# MIMXRT685S_cm33 register map
Vendor: nxp.com; File version: 1.0
CPU: CM33 r2p0, little endian, MPU, FPU, VTOR, 3 interrupt priority bits
Registers are 32-bit, read-write, reset 0x0 unless marked. A register's access mark holds for its fields unless they carry their own. Offsets are from the block's base; [hi:lo] are bit positions; {n}, {i} and the like mark numbered series.

## CMP
Base 0x40139000
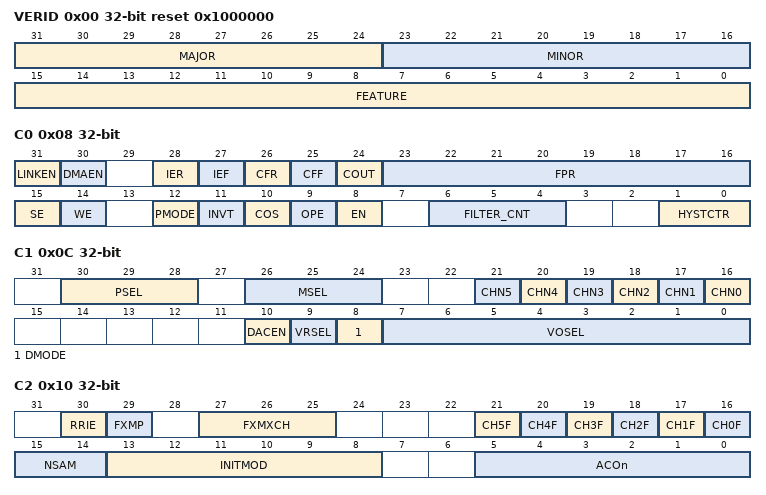
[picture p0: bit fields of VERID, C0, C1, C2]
0x00 VERID ro reset 0x1000000 — Version ID Register
  [31:24] MAJOR — Major Version Number. This read only field returns the major version number for the module specification.
  [23:16] MINOR — Minor Version Number. This read only field returns the minor version number for the module specification.
  [15:0] FEATURE — Feature Specification Number. This read only filed returns the feature set number.
0x04 PARAM ro — Parameter Register
  [31:0] PARAM — Parameter Registers. This read only filed returns the feature parameters implemented along with the Version ID register.
0x08 C0 — CMP Control Register 0
  [31] LINKEN — CMP to DAC link enable.
    0=CMP to DAC link is disabled; 1=CMP to DAC link is enabled
  [30] DMAEN — DMA Enable
    0=DMA is disabled; 1=DMA is enabled
  [28] IER — Comparator Interrupt Enable Rising
    0=Interrupt is disabled; 1=Interrupt is enabled
  [27] IEF — Comparator Interrupt Enable Falling
    0=Interrupt is disabled; 1=Interrupt is enabled
  [26] CFR write-1-clears — Analog Comparator Flag Rising
    0=A rising edge has not been detected on COUT; 1=A rising edge on COUT has occurred
  [25] CFF write-1-clears — Analog Comparator Flag Falling
    0=A falling edge has not been detected on COUT; 1=A falling edge on COUT has occurred
  [24] COUT ro — Analog Comparator Output
  [23:16] FPR — Filter Sample Period
  [15] SE — Sample Enable
    0=Sampling mode is not selected; 1=Sampling mode is selected
  [14] WE — Windowing Enable
    0=Windowing mode is not selected; 1=Windowing mode is selected
  [12] PMODE — Power Mode Select
    0=Low Speed (LS) comparison mode is selected; 1=High Speed (HS) comparison mode is selected
  [11] INVT — Comparator invert
    0=Does not invert the comparator output; 1=Inverts the comparator output
  [10] COS — Comparator Output Select
    0=Set CMPO to equal COUT (filtered comparator output); 1=Set CMPO to equal COUTA (unfiltered comparator output)
  [9] OPE — Comparator Output Pin Enable
    0=When OPE is 0, the comparator output (after window/filter settings dependent on software configuration) is not available to a packaged pin; 1=When OPE is 1, and if the software has configured the comparator to own a packaged pin, the comparator is available in a packaged pin
  [8] EN — Comparator Module Enable
    0=Analog Comparator is disabled; 1=Analog Comparator is enabled
  [6:4] FILTER_CNT — Filter Sample Count
    0=Filter is disabled. If SE = 1, then COUT is a logic zero (this is not a legal state, and is not recommended). If SE = 0, COUT = COUTA.; 1=1 consecutive sample must agree (comparator output is simply sampled); {v}={v} consecutive samples must agree (v=2..7)
  [1:0] HYSTCTR — Comparator hard block hysteresis control. See chip data sheet to get the actual hystersis value with each level
    {v}=The hard block output has level {v} hysteresis internally (v=0..3)
0x0C C1 — CMP Control Register 1
  [30:28] PSEL — Plus Input MUX Control
    0=Internal Posivite Input 0 for Plus Channel -- Internal Minus Input; {v}=External Input {v} for Plus Channel -- Reference Input {v-1} (v=1..4); 5=External Input 4 for Plus Channel -- Reference Input 4; 6=External Input 4 for Plus Channel -- Reference Input 5; 7=Internal 8b DAC output
  [26:24] MSEL — Minus Input MUX Control
    0=Internal Negative Input 0 for Minus Channel -- Internal Minus Input; {v}=External Input {v} for Minus Channel -- Reference Input {v-1} (v=1..6); 7=Internal 8b DAC output
  [n+16] CHN{n} (n=0..5) — Channel {n} input enable
  [10] DACEN — DAC Enable
    0=DAC is disabled; 1=DAC is enabled
  [9] VRSEL — Supply Voltage Reference Source Select
    0=Vin1 is selected as resistor ladder network supply reference Vin. Vin1 is from internal PMC.; 1=Vin2 is selected as resistor ladder network supply reference Vin. Vin2 is from PAD.
  [8] DMODE — DAC Mode Selection
    0=DAC is selected to work in low speed and low power mode; 1=DAC is selected to work in high speed high power mode
  [7:0] VOSEL — DAC Output Voltage Select
0x10 C2 — CMP Control Register 2
  [30] RRIE — Round-Robin interrupt enable
    0=The round-robin interrupt is disabled; 1=The round-robin interrupt is enabled when a comparison result changes from the last sample
  [29] FXMP — Fixed MUX Port
    0=The Plus port is fixed. Only the inputs to the Minus port are swept in each round.; 1=The Minus port is fixed. Only the inputs to the Plus port are swept in each round.
  [27:25] FXMXCH — Fixed channel selection
    {v}=External Reference Input {v} is selected as the fixed reference input for the fixed mux port (v=0..5); 7=The 8bit DAC is selected as the fixed reference input for the fixed mux port
  [n+16] CH{n}F write-1-clears (n=0..5)
  [15:14] NSAM — Number of sample clocks
    0=The comparison result is sampled as soon as the active channel is scanned in one round-robin clock; 1=The sampling takes place 1 round-robin clock cycle after the next cycle of the round-robin clock; 2=The sampling takes place 2 round-robin clock cycles after the next cycle of the round-robin clock; 3=The sampling takes place 3 round-robin clock cycles after the next cycle of the round-robin clock
  [13:8] INITMOD — Comparator and DAC initialization delay modulus.
  [5:0] ACOn
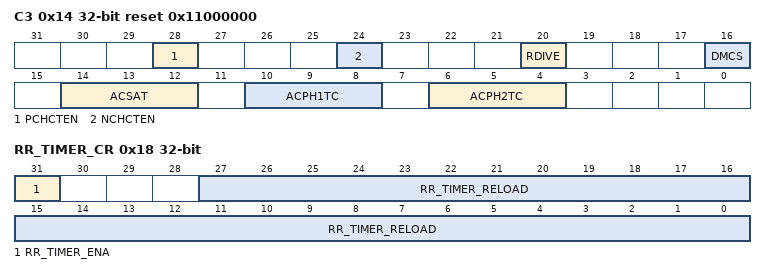
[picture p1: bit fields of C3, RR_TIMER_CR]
0x14 C3 reset 0x11000000 — CMP Control Register 3
  [28] PCHCTEN — Positive Channel Continuous Mode Enable.
    0=Positive channel is in Discrete Mode and special timing needs to be configured; 1=Positive channel is in Continuous Mode and no special timing is requried
  [24] NCHCTEN — Negative Channel Continuous Mode Enable.
    0=Negative channel is in Discrete Mode and special timing needs to be configured; 1=Negative channel is in Continuous Mode and no special timing is requried
  [20] RDIVE — Resistor Divider Enable
    0=The resistor is not enabled even when either NCHEN or PCHEN is set to1 but the actual input is in the range of 0 - 1.8v; 1=The resistor is enabled because the inputs are above 1.8v
  [16] DMCS — Discrete Mode Clock Selection
    0=Slow clock is selected for the timing generation; 1=Fast clock is selected for the timing generation
  [14:12] ACSAT — Analog Comparator Sampling Time control.
    0=The sampling time equals to T; 1=The sampling time equasl to 2*T; 2=The sampling time equasl to 4*T; 3=The sampling time equasl to 8*T; 4=The sampling time equasl to 16*T; 5=The sampling time equasl to 32*T; 6=The sampling time equasl to 64*T; 7=The sampling time equasl to 256*T
  [10:8] ACPH1TC — Analog Comparator Phase1 Timing Control.
    0=Phase1 active time in one sampling period equals to T; 1=Phase1 active time in one sampling period equals to 2*T; 2=Phase1 active time in one sampling period equals to 4*T; 3=Phase1 active time in one sampling period equals to 8*T; 4=Phase1 active time in one sampling period equals to T; 5=Phase1 active time in one sampling period equals to T; 6=Phase1 active time in one sampling period equals to T; 7=Phase1 active time in one sampling period equals to 0
  [6:4] ACPH2TC — Analog Comparator Phase2 Timing Control.
    0=Phase2 active time in one sampling period equals to T; 1=Phase2 active time in one sampling period equals to 2*T; 2=Phase2 active time in one sampling period equals to 4*T; 3=Phase2 active time in one sampling period equals to 8*T; 4=Phase2 active time in one sampling period equals to 16*T; 5=Phase2 active time in one sampling period equals to 32*T; 6=Phase2 active time in one sampling period equals to 64*T; 7=Phase2 active time in one sampling period equals to 16*T
0x18 RR_TIMER_CR — Round-Robin Timer Control Register
  [31] RR_TIMER_ENA — RR_TIMER enable. When low, rr_timer count will be held at zero. When set, timer will commence continuous, repetitive counting beginning with the 1st or 2nd rising edge of the 32 KHz rr_clock.1
  [27:0] RR_TIMER_RELOAD — This field establishes the repetitive count rate for the timer. Each time the timer counts down to zero it is reloaded with this value. The rr_trig signal will be generated at a rate of (rr_timer_reload + 1) times the rr_clock period (typically 30.6 uS)
